# CY8C5868AXI_LP035 register map
File version: 0.1
CY8C58LP
Registers are 8-bit, read-write, no defined reset value unless marked. A register's access mark holds for its fields unless they carry their own. Offsets are from the block's base; lines under a group give offsets from that group; [hi:lo] are bit positions; {n}, {i} and the like mark numbered series; 'fields as' and 'values as' point back to an identical list; <NAME> marks a mode.

## Memory map
0x00000000 UART
0x00000000 HSYNC
0x00000000 HORIZ
0x00000000 VERT
0x00000000 VSYNC
0x40006579 PIXEL

## PIXEL
Base 0x40006579
0x00 PIXEL_CONTROL_REG

## UART
Base 0x00000000
0x4000644A TX_UART_TX_DATA — TX Data Register
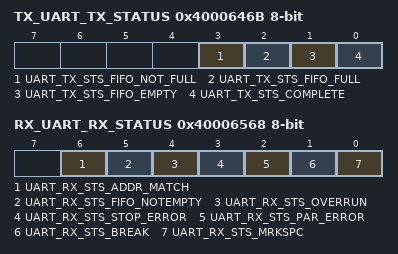
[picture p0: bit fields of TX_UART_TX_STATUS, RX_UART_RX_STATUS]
0x4000646B TX_UART_TX_STATUS — TX status register
  [3] UART_TX_STS_FIFO_NOT_FULL ro, [2] UART_TX_STS_FIFO_FULL ro, [1] UART_TX_STS_FIFO_EMPTY ro, [0] UART_TX_STS_COMPLETE ro
0x40006528 RX_UART_RX_ADDRESS1 — RX Address1 Register
0x40006538 RX_UART_RX_ADDRESS2 — RX Address2 Register
0x40006548 RX_UART_RX_DATA — RX Data Register
0x40006568 RX_UART_RX_STATUS — RX status register
  [6] UART_RX_STS_ADDR_MATCH ro, [5] UART_RX_STS_FIFO_NOTEMPTY ro, [4] UART_RX_STS_OVERRUN ro, [3] UART_RX_STS_STOP_ERROR ro, [2] UART_RX_STS_PAR_ERROR ro, [1] UART_RX_STS_BREAK ro, [0] UART_RX_STS_MRKSPC ro

## HSYNC
Base 0x00000000
0x40006429 HSYNC_COMPARE_Reg_ — UDB.D0 - Assigned Compare Value
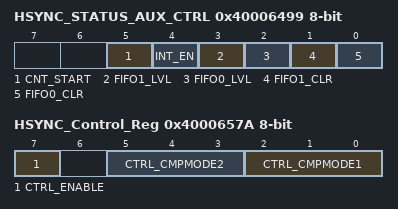
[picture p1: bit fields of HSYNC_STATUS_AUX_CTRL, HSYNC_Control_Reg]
0x40006499 HSYNC_STATUS_AUX_CTRL — UDB Auxilliary Control Register
  [5] CNT_START — FIFO0 clear
    0=E_CNT_START0 (Disable counter); 1=E_CNT_START1 (Enable counter)
  [4] INT_EN
    0=E_INT_EN0 (Interrupt disabled); 1=E_INT_EN1 (Interrupt enabled)
  [3] FIFO1_LVL — FIFO level
    0=E_FIFO_LVL_0 (FIFO LVL: input mode: FIFO not full; output mode: FIFO not empty); 1=E_FIFO_LVL_1 (FIFO LVL: input mode: FIFO at least 1/2 empty; output mode: FIFO at least 1/2 full)
  [2] FIFO0_LVL — FIFO level
    values as FIFO1_LVL
  [1] FIFO1_CLR — FIFO1 clear
    0=E_FIFO_CLR_0 (Normal FIFO operation); 1=E_FIFO_CLR_1 (Clear FIFO state)
  [0] FIFO0_CLR — FIFO0 clear
    values as FIFO1_CLR
0x4000657A HSYNC_Control_Reg — UDB Control Register - Assigned Control Register Value
  [7] CTRL_ENABLE — Enable the PWM
  [5:3] CTRL_CMPMODE2 — Compare mode 2
  [2:0] CTRL_CMPMODE1 — Compare mode 1

## HORIZ
Base 0x00000000
0x40006428 HORIZ__COMPARE1 — UDB.D0 - Assigned Compare1 Value
0x40006438 HORIZ__COMPARE2 — UDB.D1 - Assigned Compare2 Value
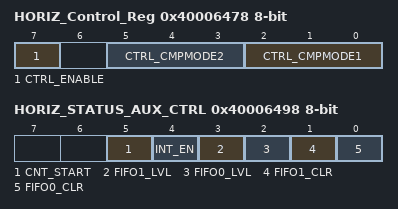
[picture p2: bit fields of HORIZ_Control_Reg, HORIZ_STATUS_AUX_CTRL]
0x40006478 HORIZ_Control_Reg — UDB Control Register - Assigned Control Register Value
  [7] CTRL_ENABLE — Enable the PWM
  [5:3] CTRL_CMPMODE2 — Compare mode 2
  [2:0] CTRL_CMPMODE1 — Compare mode 1
0x40006498 HORIZ_STATUS_AUX_CTRL — UDB Auxilliary Control Register
  fields as HSYNC.HSYNC_STATUS_AUX_CTRL

## VERT
Base 0x00000000
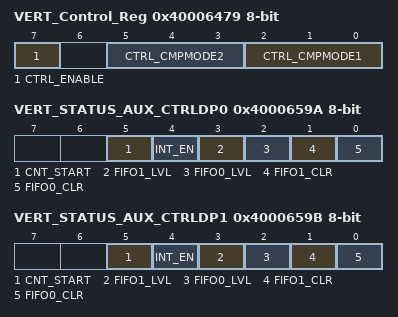
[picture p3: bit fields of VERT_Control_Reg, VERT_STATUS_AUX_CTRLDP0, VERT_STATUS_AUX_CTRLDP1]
0x40006479 VERT_Control_Reg — UDB Control Register - Assigned Control Register Value
  [7] CTRL_ENABLE — Enable the PWM
  [5:3] CTRL_CMPMODE2 — Compare mode 2
  [2:0] CTRL_CMPMODE1 — Compare mode 1
0x4000652A VERT_COMPARE_Reg 16-bit — UDB.D0 - Assigned Compare Value
0x4000659A VERT_STATUS_AUX_CTRLDP0 — UDB Auxilliary Control Register
  fields as HSYNC.HSYNC_STATUS_AUX_CTRL
0x4000659B VERT_STATUS_AUX_CTRLDP1 — UDB Auxilliary Control Register
  fields as HSYNC.HSYNC_STATUS_AUX_CTRL

## VSYNC
Base 0x00000000
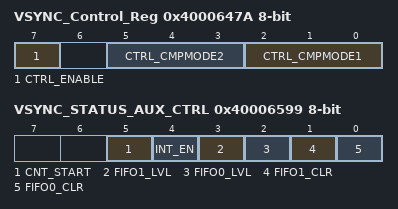
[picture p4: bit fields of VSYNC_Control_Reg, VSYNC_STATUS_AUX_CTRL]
0x4000647A VSYNC_Control_Reg — UDB Control Register - Assigned Control Register Value
  [7] CTRL_ENABLE — Enable the PWM
  [5:3] CTRL_CMPMODE2 — Compare mode 2
  [2:0] CTRL_CMPMODE1 — Compare mode 1
0x40006529 VSYNC_COMPARE_Reg_ — UDB.D0 - Assigned Compare Value
0x40006599 VSYNC_STATUS_AUX_CTRL — UDB Auxilliary Control Register
  fields as HSYNC.HSYNC_STATUS_AUX_CTRL
